# STM32WB55x register map
File version: 1.0
CPU: CM4 r0p1, little endian, 4 interrupt priority bits
Registers are 32-bit, read-write, reset 0x0 unless marked. A register's access mark holds for its fields unless they carry their own. Offsets are from the block's base; [hi:lo] are bit positions; {n}, {i} and the like mark numbered series; 'fields as' and 'values as' point back to an identical list.

## DMA1
Base 0x40020000
Same registers: DMA2 0x40020400
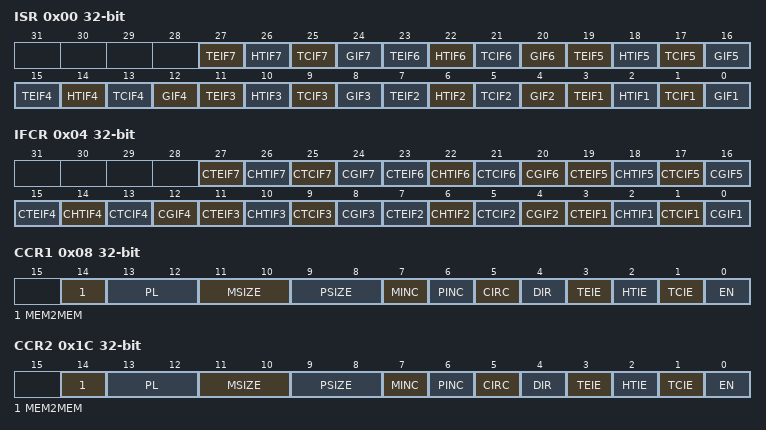
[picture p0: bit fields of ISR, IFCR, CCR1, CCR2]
0x00 ISR
  [4n-1] TEIF{n} (n=1..7), [4n-2] HTIF{n} (n=1..7), [4n-3] TCIF{n} (n=1..7), [4n-4] GIF{n} (n=1..7)
0x04 IFCR
  [4n-1] CTEIF{n} (n=1..7), [4n-2] CHTIF{n} (n=1..7), [4n-3] CTCIF{n} (n=1..7), [4n-4] CGIF{n} (n=1..7)
0x08 CCR1
  [14] MEM2MEM, [13:12] PL, [11:10] MSIZE, [9:8] PSIZE, [7] MINC, [6] PINC, [5] CIRC, [4] DIR, [3] TEIE, [2] HTIE, [1] TCIE, [0] EN
0x0C CNDTR1
  [15:0] NDTR
0x10 CPAR1
  [31:0] PA
{0x0+0x14*i} CMAR{i} (i=1..7)
  [31:0] MA
0x1C CCR2
  fields as CCR1
0x20 CNDTR2
  [15:0] NDTR
0x24 CPAR2
  [31:0] PA
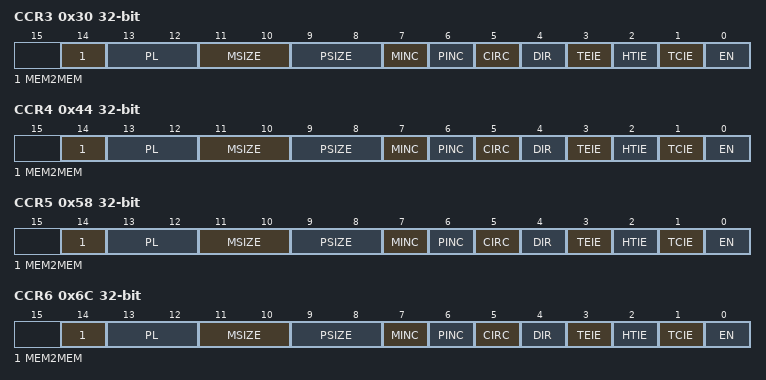
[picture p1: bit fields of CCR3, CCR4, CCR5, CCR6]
0x30 CCR3
  fields as CCR1
0x34 CNDTR3
  [15:0] NDTR
0x38 CPAR3
  [31:0] PA
0x44 CCR4
  fields as CCR1
0x48 CNDTR4
  [15:0] NDTR
0x4C CPAR4
  [31:0] PA
0x58 CCR5
  fields as CCR1
0x5C CNDTR5
  [15:0] NDTR
0x60 CPAR5
  [31:0] PA
0x6C CCR6
  fields as CCR1
0x70 CNDTR6
  [15:0] NDTR
0x74 CPAR6
  [31:0] PA
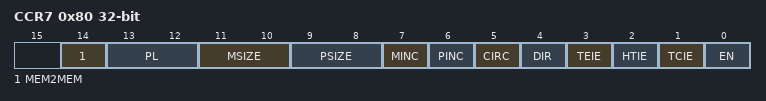
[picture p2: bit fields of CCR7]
0x80 CCR7
  fields as CCR1
0x84 CNDTR7
  [15:0] NDTR
0x88 CPAR7
  [31:0] PA

## SPI1
Base 0x40013000
Same registers: SPI2 0x40003800
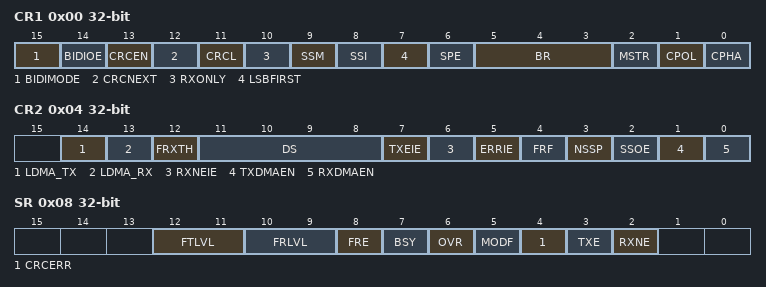
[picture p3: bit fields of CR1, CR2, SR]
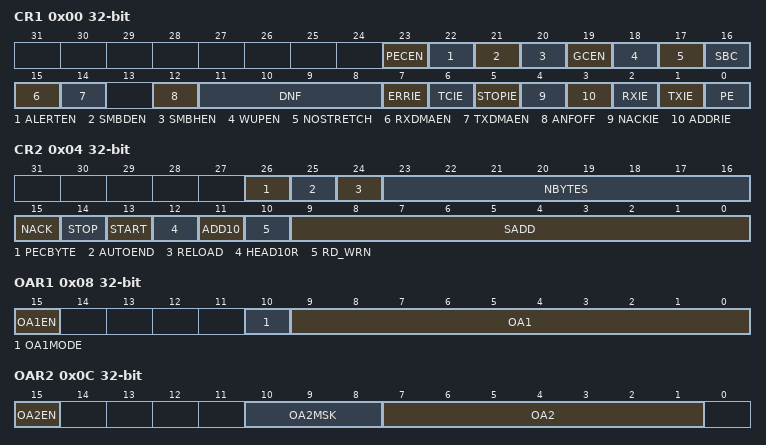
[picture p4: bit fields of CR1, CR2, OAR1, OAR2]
0x00 CR1
  [15] BIDIMODE, [14] BIDIOE, [13] CRCEN, [12] CRCNEXT, [11] CRCL, [10] RXONLY, [9] SSM, [8] SSI, [7] LSBFIRST, [6] SPE, [5:3] BR, [2] MSTR, [1] CPOL, [0] CPHA
0x04 CR2
  [14] LDMA_TX, [13] LDMA_RX, [12] FRXTH, [11:8] DS, [7] TXEIE, [6] RXNEIE, [5] ERRIE, [4] FRF, [3] NSSP, [2] SSOE, [1] TXDMAEN, [0] RXDMAEN
0x08 SR
  [12:11] FTLVL, [10:9] FRLVL, [8] FRE, [7] BSY, [6] OVR, [5] MODF, [4] CRCERR, [3] TXE, [2] RXNE
0x0C DR
  [15:0] DR
0x10 CRCPR
  [15:0] CRCPOLY
0x14 RXCRCR
  [15:0] RXCRC
0x18 TXCRCR
  [15:0] TXCRC

## I2C1
Base 0x40005400
Same registers: I2C3 0x40005C00
0x00 CR1
  [23] PECEN, [22] ALERTEN, [21] SMBDEN, [20] SMBHEN, [19] GCEN, [18] WUPEN, [17] NOSTRETCH, [16] SBC, [15] RXDMAEN, [14] TXDMAEN, [12] ANFOFF, [11:8] DNF, [7] ERRIE, [6] TCIE, [5] STOPIE, [4] NACKIE, [3] ADDRIE, [2] RXIE, [1] TXIE, [0] PE
0x04 CR2
  [26] PECBYTE, [25] AUTOEND, [24] RELOAD, [23:16] NBYTES, [15] NACK, [14] STOP, [13] START, [12] HEAD10R, [11] ADD10, [10] RD_WRN, [9:0] SADD
0x08 OAR1
  [15] OA1EN, [10] OA1MODE, [9:0] OA1
0x0C OAR2
  [15] OA2EN, [10:8] OA2MSK, [7:1] OA2
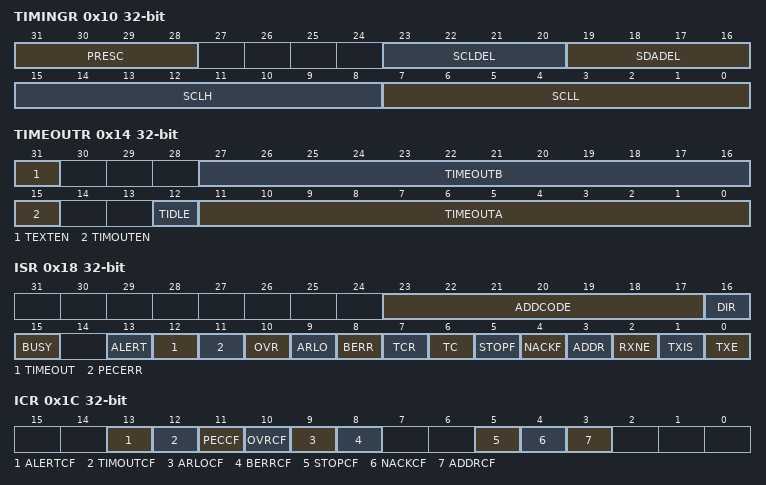
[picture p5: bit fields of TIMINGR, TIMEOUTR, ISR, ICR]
0x10 TIMINGR
  [31:28] PRESC, [23:20] SCLDEL, [19:16] SDADEL, [15:8] SCLH, [7:0] SCLL
0x14 TIMEOUTR
  [31] TEXTEN, [27:16] TIMEOUTB, [15] TIMOUTEN, [12] TIDLE, [11:0] TIMEOUTA
0x18 ISR
  [23:17] ADDCODE, [16] DIR, [15] BUSY, [13] ALERT, [12] TIMEOUT, [11] PECERR, [10] OVR, [9] ARLO, [8] BERR, [7] TCR, [6] TC, [5] STOPF, [4] NACKF, [3] ADDR, [2] RXNE, [1] TXIS, [0] TXE
0x1C ICR
  [13] ALERTCF, [12] TIMOUTCF, [11] PECCF, [10] OVRCF, [9] ARLOCF, [8] BERRCF, [5] STOPCF, [4] NACKCF, [3] ADDRCF
0x20 PECR
  [7:0] PEC
0x24 RXDR
  [7:0] RXDATA
0x28 TXDR
  [7:0] TXDATA

## COMP
Base 0x40010200
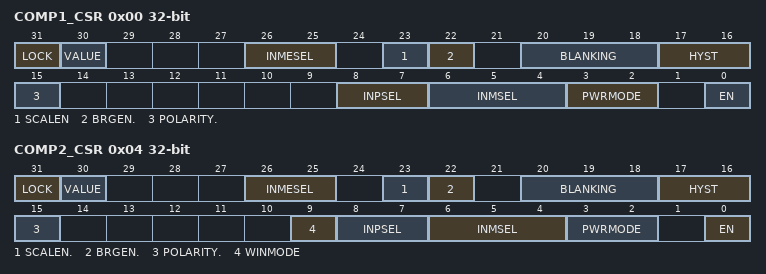
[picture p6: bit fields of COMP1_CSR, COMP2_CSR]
0x00 COMP1_CSR
  [31] LOCK, [30] VALUE, [26:25] INMESEL, [23] SCALEN, [22] BRGEN., [20:18] BLANKING, [17:16] HYST, [15] POLARITY., [8:7] INPSEL, [6:4] INMSEL, [3:2] PWRMODE, [0] EN
0x04 COMP2_CSR
  [31] LOCK, [30] VALUE, [26:25] INMESEL, [23] SCALEN., [22] BRGEN., [20:18] BLANKING, [17:16] HYST, [15] POLARITY., [9] WINMODE, [8:7] INPSEL, [6:4] INMSEL, [3:2] PWRMODE, [0] EN

## LCD
Base 0x40002400
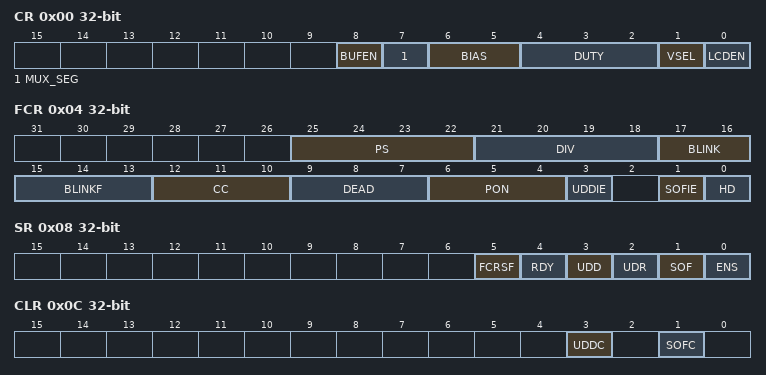
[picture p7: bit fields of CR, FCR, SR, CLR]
0x00 CR
  [8] BUFEN, [7] MUX_SEG, [6:5] BIAS, [4:2] DUTY, [1] VSEL, [0] LCDEN
0x04 FCR
  [25:22] PS, [21:18] DIV, [17:16] BLINK, [15:13] BLINKF, [12:10] CC, [9:7] DEAD, [6:4] PON, [3] UDDIE, [1] SOFIE, [0] HD
0x08 SR
  [5] FCRSF, [4] RDY, [3] UDD, [2] UDR, [1] SOF, [0] ENS
0x0C CLR
  [3] UDDC, [1] SOFC
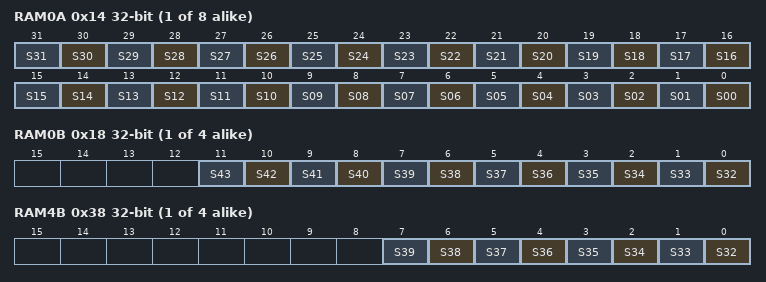
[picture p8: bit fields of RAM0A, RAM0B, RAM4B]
{0x14+8i} RAM{i}A (i=0..7)
  [n] S{n:02} (n=0..31)
{0x18+8i} RAM{i}B (i=0..3)
  [n-32] S{n} (n=32..43)
{0x18+8i} RAM{i}B (i=4..7)
  [n-32] S{n} (n=32..39)

## AES1
Base 0x50050400
Same registers: AES2 0x58001800
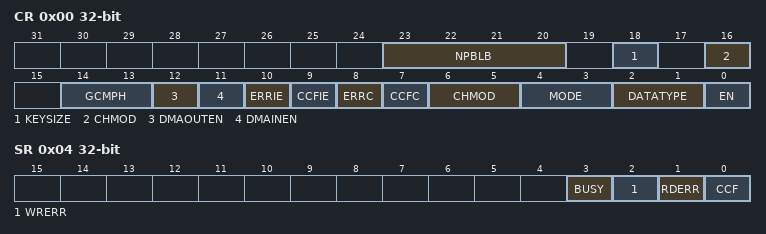
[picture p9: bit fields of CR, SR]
0x00 CR
  [23:20] NPBLB, [18] KEYSIZE, [16] CHMOD, [14:13] GCMPH, [12] DMAOUTEN, [11] DMAINEN, [10] ERRIE, [9] CCFIE, [8] ERRC, [7] CCFC, [6:5] CHMOD, [4:3] MODE, [2:1] DATATYPE, [0] EN
0x04 SR
  [3] BUSY, [2] WRERR, [1] RDERR, [0] CCF
0x08 DINR
  [31:0] DIN
0x0C DOUTR
  [31:0] DOUT
{0x10+4i} KEYR{i} (i=0..3)
  [31:0] KEY
{0x20+4i} IVR{i} (i=0..3)
  [31:0] IVI
{0x20+4i} KEYR{i} (i=4..7)
  [31:0] KEY
{0x40+4i} SUSP{i}R (i=0..7)
  [31:0] SUSP{i}
